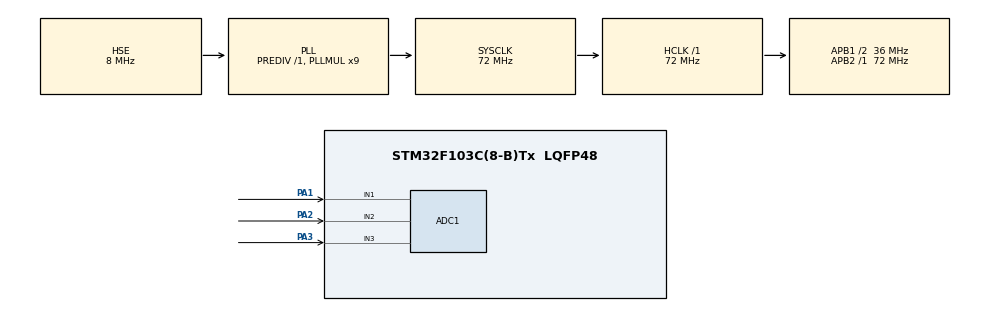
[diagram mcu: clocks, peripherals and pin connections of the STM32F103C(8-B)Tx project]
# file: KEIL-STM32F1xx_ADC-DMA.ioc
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ADC1.AutoInjectedConv=DISABLE
ADC1.Channel-0\#ChannelRegularConversion=ADC_CHANNEL_1
ADC1.Channel-1\#ChannelRegularConversion=ADC_CHANNEL_2
ADC1.Channel-2\#ChannelRegularConversion=ADC_CHANNEL_3
ADC1.ContinuousConvMode=ENABLE
ADC1.InjectedDiscontinuousConvMode=DISABLE
ADC1.NbrOfConversion=3
ADC1.NbrOfConversionFlag=1
ADC1.Rank-0\#ChannelRegularConversion=1
ADC1.Rank-1\#ChannelRegularConversion=2
ADC1.Rank-2\#ChannelRegularConversion=3
ADC1.SamplingTime-0\#ChannelRegularConversion=ADC_SAMPLETIME_55CYCLES_5
ADC1.SamplingTime-1\#ChannelRegularConversion=ADC_SAMPLETIME_55CYCLES_5
ADC1.SamplingTime-2\#ChannelRegularConversion=ADC_SAMPLETIME_55CYCLES_5
ADC1.master=1
Dma.ADC1.0.Direction=DMA_PERIPH_TO_MEMORY
Dma.ADC1.0.Instance=DMA1_Channel1
Dma.ADC1.0.MemDataAlignment=DMA_MDATAALIGN_HALFWORD
Dma.ADC1.0.MemInc=DMA_MINC_ENABLE
Dma.ADC1.0.Mode=DMA_CIRCULAR
Dma.ADC1.0.PeriphDataAlignment=DMA_PDATAALIGN_HALFWORD
Dma.ADC1.0.PeriphInc=DMA_PINC_DISABLE
Dma.ADC1.0.Priority=DMA_PRIORITY_LOW
Dma.Request0=ADC1
Mcu.Family=STM32F1
Mcu.Name=STM32F103C(8-B)Tx
Mcu.Package=LQFP48
NVIC.DMA1_Channel1_IRQn=true\:0\:0\:false\:false\:true
NVIC.PriorityGroup=NVIC_PRIORITYGROUP_4
PA1.Signal=ADCx_IN1
PA13.Mode=Serial_Wire
PA13.Signal=SYS_JTMS-SWDIO
PA14.Mode=Serial_Wire
PA14.Signal=SYS_JTCK-SWCLK
PA2.Signal=ADCx_IN2
PA3.Signal=ADCx_IN3
PD0-OSC_IN.Mode=HSE-External-Oscillator
PD0-OSC_IN.Signal=RCC_OSC_IN
PD1-OSC_OUT.Mode=HSE-External-Oscillator
PD1-OSC_OUT.Signal=RCC_OSC_OUT
ProjectManager.HeapSize=0x200
ProjectManager.StackSize=0x400
ProjectManager.TargetToolchain=MDK-ARM V5
RCC.ADCPresc=RCC_ADCPCLK2_DIV6
RCC.AHBCLKDivider=RCC_SYSCLK_DIV1
RCC.AHBFreq_Value=72000000
RCC.APB1CLKDivider=RCC_HCLK_DIV2
RCC.APB1Freq_Value=36000000
RCC.APB1TimFreq_Value=72000000
RCC.APB2CLKDivider=RCC_HCLK_DIV1
RCC.APB2Freq_Value=72000000
RCC.APB2TimFreq_Value=72000000
RCC.ClockTypeHCLK=RCC_CLOCKTYPE_HCLK
RCC.ClockTypePCLK1=RCC_CLOCKTYPE_PCLK1
RCC.ClockTypePCLK2=RCC_CLOCKTYPE_PCLK2
RCC.EnableHSE=true
RCC.EnableHSERTCDevisor=false
RCC.EnableLSE=false
RCC.EnableLSERTC=false
RCC.EnableMCOMultDivisor=false
RCC.HCLKFreq_Value=72000000
RCC.HSEState=RCC_HSE_ON
RCC.HSIState=RCC_HSI_ON
RCC.IWDGEnable=false
RCC.LSIState=RCC_LSI_OFF
RCC.MCOEnable=false
RCC.OscillatorTypeHSE=RCC_OSCILLATORTYPE_HSE
RCC.OscillatorTypeHSI=RCC_OSCILLATORTYPE_HSI
RCC.PLLMUL=RCC_PLL_MUL9
RCC.PLLSource=RCC_PLLSOURCE_HSE
RCC.PLLSourceVirtual=RCC_PLLSOURCE_HSE
RCC.PLLState=RCC_PLL_ON
RCC.RTCEnable=false
RCC.SYSCLKFreq_VALUE=72000000
RCC.SYSCLKSource=RCC_SYSCLKSOURCE_PLLCLK
RCC.TimSys_Div=SYSTICK_CLKSOURCE_HCLK
RCC.USBFreq_Value=72000000
SH.ADCx_IN1.0=ADC1_IN1,IN1
SH.ADCx_IN2.0=ADC1_IN2,IN2
SH.ADCx_IN3.0=ADC1_IN3,IN3
board=KEIL-STM32F1xx_ADC-DMA

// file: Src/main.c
/**
  ******************************************************************************
  * File Name          : main.c
  * Description        : Main program body
  ******************************************************************************
  *
  * COPYRIGHT(c) 2017 STMicroelectronics
  *
  * Redistribution and use in source and binary forms, with or without modification,
  * are permitted provided that the following conditions are met:
  *   1. Redistributions of source code must retain the above copyright notice,
  *      this list of conditions and the following disclaimer.
  *   2. Redistributions in binary form must reproduce the above copyright notice,
  *      this list of conditions and the following disclaimer in the documentation
  *      and/or other materials provided with the distribution.
  *   3. Neither the name of STMicroelectronics nor the names of its contributors
  *      may be used to endorse or promote products derived from this software
  *      without specific prior written permission.
  *
  * THIS SOFTWARE IS PROVIDED BY THE COPYRIGHT HOLDERS AND CONTRIBUTORS "AS IS"
  * AND ANY EXPRESS OR IMPLIED WARRANTIES, INCLUDING, BUT NOT LIMITED TO, THE
  * IMPLIED WARRANTIES OF MERCHANTABILITY AND FITNESS FOR A PARTICULAR PURPOSE ARE
  * DISCLAIMED. IN NO EVENT SHALL THE COPYRIGHT HOLDER OR CONTRIBUTORS BE LIABLE
  * FOR ANY DIRECT, INDIRECT, INCIDENTAL, SPECIAL, EXEMPLARY, OR CONSEQUENTIAL
  * DAMAGES (INCLUDING, BUT NOT LIMITED TO, PROCUREMENT OF SUBSTITUTE GOODS OR
  * SERVICES; LOSS OF USE, DATA, OR PROFITS; OR BUSINESS INTERRUPTION) HOWEVER
  * CAUSED AND ON ANY THEORY OF LIABILITY, WHETHER IN CONTRACT, STRICT LIABILITY,
  * OR TORT (INCLUDING NEGLIGENCE OR OTHERWISE) ARISING IN ANY WAY OUT OF THE USE
  * OF THIS SOFTWARE, EVEN IF ADVISED OF THE POSSIBILITY OF SUCH DAMAGE.
  *
  ******************************************************************************
  */
#include "main.h"
#include "stm32f1xx_hal.h"

ADC_HandleTypeDef hadc1;
DMA_HandleTypeDef hdma_adc1;

/* USER CODE BEGIN PV */
/* Private variables ---------------------------------------------------------*/
uint16_t ADC_1;
uint16_t ADC_2;
uint16_t ADC_3;
volatile uint16_t ADC_Buff[3];
/* USER CODE END PV */

void SystemClock_Config(void);
void Error_Handler(void);
static void MX_GPIO_Init(void);
static void MX_DMA_Init(void);
static void MX_ADC1_Init(void);

/* USER CODE BEGIN PFP */
/* Private function prototypes -----------------------------------------------*/

/* USER CODE END PFP */

int main(void)
{

  /* MCU Configuration----------------------------------------------------------*/

  /* Reset of all peripherals, Initializes the Flash interface and the Systick. */
  HAL_Init();

  /* Configure the system clock */
  SystemClock_Config();

  /* Initialize all configured peripherals */
  MX_GPIO_Init();
  MX_DMA_Init();
  MX_ADC1_Init();

  /* Infinite loop */
  while (1)
  {

  /* USER CODE BEGIN 3 */
		ADC_1 = ADC_Buff[0];
		ADC_2 = ADC_Buff[1];
		ADC_3 = ADC_Buff[2];
  }
  /* USER CODE END 3 */

}

/** System Clock Configuration
*/
void SystemClock_Config(void)
{

  RCC_OscInitTypeDef RCC_OscInitStruct;
  RCC_ClkInitTypeDef RCC_ClkInitStruct;
  RCC_PeriphCLKInitTypeDef PeriphClkInit;

    /**Initializes the CPU, AHB and APB busses clocks
    */
  RCC_OscInitStruct.OscillatorType = RCC_OSCILLATORTYPE_HSE;
  RCC_OscInitStruct.HSEState = RCC_HSE_ON;
  RCC_OscInitStruct.HSEPredivValue = RCC_HSE_PREDIV_DIV1;
  RCC_OscInitStruct.PLL.PLLState = RCC_PLL_ON;
  RCC_OscInitStruct.PLL.PLLSource = RCC_PLLSOURCE_HSE;
  RCC_OscInitStruct.PLL.PLLMUL = RCC_PLL_MUL9;
  if (HAL_RCC_OscConfig(&RCC_OscInitStruct) != HAL_OK)
  {
    Error_Handler();
  }

    /**Initializes the CPU, AHB and APB busses clocks
    */
  RCC_ClkInitStruct.ClockType = RCC_CLOCKTYPE_HCLK|RCC_CLOCKTYPE_SYSCLK
                              |RCC_CLOCKTYPE_PCLK1|RCC_CLOCKTYPE_PCLK2;
  RCC_ClkInitStruct.SYSCLKSource = RCC_SYSCLKSOURCE_PLLCLK;
  RCC_ClkInitStruct.AHBCLKDivider = RCC_SYSCLK_DIV1;
  RCC_ClkInitStruct.APB1CLKDivider = RCC_HCLK_DIV2;
  RCC_ClkInitStruct.APB2CLKDivider = RCC_HCLK_DIV1;

  if (HAL_RCC_ClockConfig(&RCC_ClkInitStruct, FLASH_LATENCY_2) != HAL_OK)
  {
    Error_Handler();
  }

  PeriphClkInit.PeriphClockSelection = RCC_PERIPHCLK_ADC;
  PeriphClkInit.AdcClockSelection = RCC_ADCPCLK2_DIV6;
  if (HAL_RCCEx_PeriphCLKConfig(&PeriphClkInit) != HAL_OK)
  {
    Error_Handler();
  }

    /**Configure the Systick interrupt time
    */
  HAL_SYSTICK_Config(HAL_RCC_GetHCLKFreq()/1000);

    /**Configure the Systick
    */
  HAL_SYSTICK_CLKSourceConfig(SYSTICK_CLKSOURCE_HCLK);

  /* SysTick_IRQn interrupt configuration */
  HAL_NVIC_SetPriority(SysTick_IRQn, 0, 0);
}

/* ADC1 init function */
static void MX_ADC1_Init(void)
{

  ADC_ChannelConfTypeDef sConfig;

    /**Common config
    */
  hadc1.Instance = ADC1;
  hadc1.Init.ScanConvMode = ADC_SCAN_ENABLE;
  hadc1.Init.ContinuousConvMode = ENABLE;
  hadc1.Init.DiscontinuousConvMode = DISABLE;
  hadc1.Init.ExternalTrigConv = ADC_SOFTWARE_START;
  hadc1.Init.DataAlign = ADC_DATAALIGN_RIGHT;
  hadc1.Init.NbrOfConversion = 3;
  if (HAL_ADC_Init(&hadc1) != HAL_OK)
  {
    Error_Handler();
  }

    /**Configure Regular Channel
    */
  sConfig.Channel = ADC_CHANNEL_1;
  sConfig.Rank = 1;
  sConfig.SamplingTime = ADC_SAMPLETIME_55CYCLES_5;
  if (HAL_ADC_ConfigChannel(&hadc1, &sConfig) != HAL_OK)
  {
    Error_Handler();
  }

    /**Configure Regular Channel
    */
  sConfig.Channel = ADC_CHANNEL_2;
  sConfig.Rank = 2;
  if (HAL_ADC_ConfigChannel(&hadc1, &sConfig) != HAL_OK)
  {
    Error_Handler();
  }

    /**Configure Regular Channel
    */
  sConfig.Channel = ADC_CHANNEL_3;
  sConfig.Rank = 3;
  if (HAL_ADC_ConfigChannel(&hadc1, &sConfig) != HAL_OK)
  {
    Error_Handler();
  }

}

static void MX_DMA_Init(void)
{
  /* DMA controller clock enable */
  __HAL_RCC_DMA1_CLK_ENABLE();

  /* DMA interrupt init */
  /* DMA1_Channel1_IRQn interrupt configuration */
  HAL_NVIC_SetPriority(DMA1_Channel1_IRQn, 0, 0);
  HAL_NVIC_EnableIRQ(DMA1_Channel1_IRQn);

}

/** Configure pins as
        * Analog
        * Input
        * Output
        * EVENT_OUT
        * EXTI
*/
static void MX_GPIO_Init(void)
{

  /* GPIO Ports Clock Enable */
  __HAL_RCC_GPIOD_CLK_ENABLE();
  __HAL_RCC_GPIOA_CLK_ENABLE();

}

void Error_Handler(void)
{
  while(1)
  {
  }
}

/************************ (C) COPYRIGHT STMicroelectronics *****END OF FILE****/
